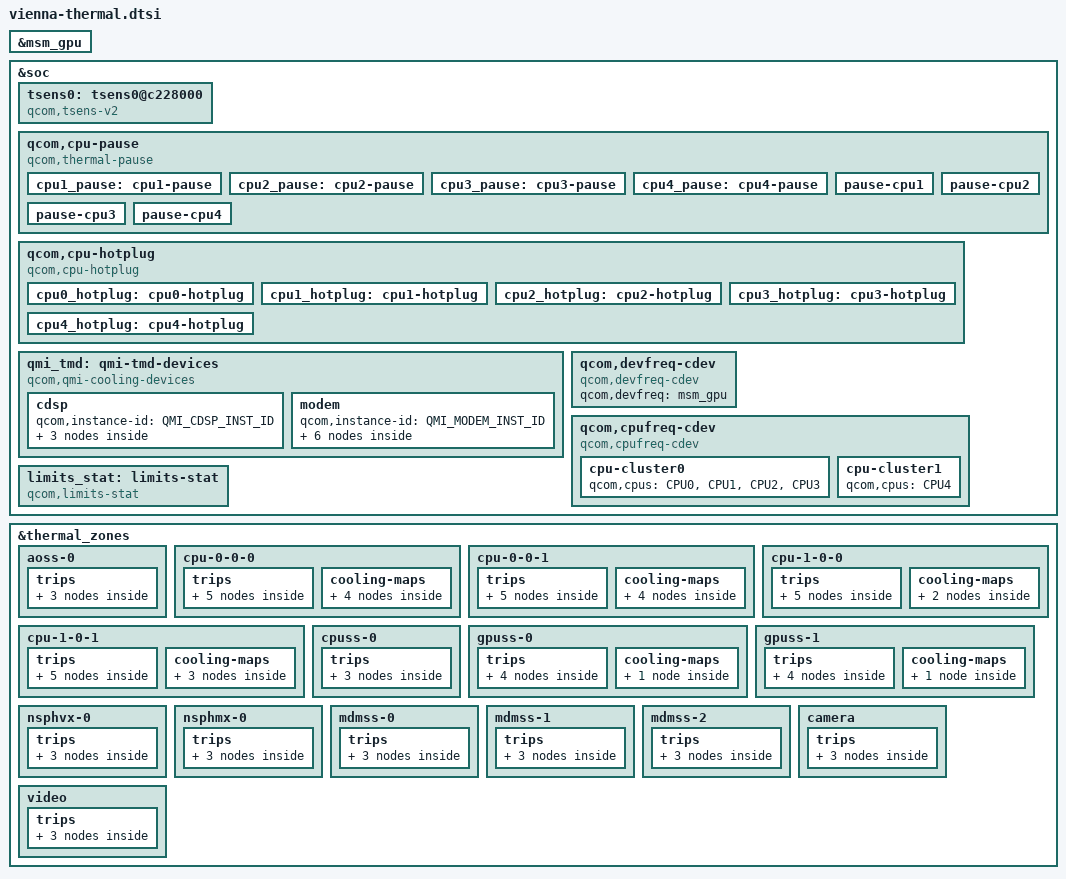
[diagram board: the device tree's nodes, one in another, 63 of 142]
// SPDX-License-Identifier: BSD-3-Clause
/*
 * Copyright (c) Qualcomm Technologies, Inc. and/or its subsidiaries.
 */

#include <dt-bindings/thermal/thermal_qti.h>

&msm_gpu {
	#cooling-cells = <2>;
};

&soc {
	tsens0: tsens0@c228000 {
		compatible = "qcom,tsens-v2";
		reg = <0xc228000 0x1ff>, /* TM */
				<0xc222000 0x1ff>; /* SROT */
		#qcom,sensors = <16>;
		interrupts = <GIC_SPI 482 IRQ_TYPE_LEVEL_HIGH>,
				<GIC_SPI 288 IRQ_TYPE_LEVEL_HIGH>;
		interrupt-names = "uplow","critical";
		#thermal-sensor-cells = <1>;
	};

	qcom,cpu-pause {
		compatible = "qcom,thermal-pause";

		cpu1_pause: cpu1-pause {
			qcom,cpus = <&CPU1>;
			qcom,cdev-alias = "thermal-pause-2";
			#cooling-cells = <2>;
		};

		cpu2_pause: cpu2-pause {
			qcom,cpus = <&CPU2>;
			qcom,cdev-alias = "thermal-pause-4";
			#cooling-cells = <2>;
		};

		cpu3_pause: cpu3-pause {
			qcom,cpus = <&CPU3>;
			qcom,cdev-alias = "thermal-pause-8";
			#cooling-cells = <2>;
		};

		cpu4_pause: cpu4-pause {
			qcom,cpus = <&CPU4>;
			qcom,cdev-alias = "thermal-pause-10";
			#cooling-cells = <2>;
		};


		/* Thermal-engine cooling devices */

		pause-cpu1 {
			qcom,cpus = <&CPU1>;
			qcom,cdev-alias = "pause-cpu1";
		};

		pause-cpu2 {
			qcom,cpus = <&CPU2>;
			qcom,cdev-alias = "pause-cpu2";
		};

		pause-cpu3 {
			qcom,cpus = <&CPU3>;
			qcom,cdev-alias = "pause-cpu3";
		};

		pause-cpu4 {
			qcom,cpus = <&CPU4>;
			qcom,cdev-alias = "pause-cpu4";
		};

	};

	qcom,cpu-hotplug {
		compatible = "qcom,cpu-hotplug";

		cpu0_hotplug: cpu0-hotplug {
			qcom,cpu = <&CPU0>;
			qcom,cdev-alias = "cpu-hotplug0";
			#cooling-cells = <2>;
		};

		cpu1_hotplug: cpu1-hotplug {
			qcom,cpu = <&CPU1>;
			qcom,cdev-alias = "cpu-hotplug1";
			#cooling-cells = <2>;
		};

		cpu2_hotplug: cpu2-hotplug {
			qcom,cpu = <&CPU2>;
			qcom,cdev-alias = "cpu-hotplug2";
			#cooling-cells = <2>;
		};

		cpu3_hotplug: cpu3-hotplug {
			qcom,cpu = <&CPU3>;
			qcom,cdev-alias = "cpu-hotplug3";
			#cooling-cells = <2>;
		};

		cpu4_hotplug: cpu4-hotplug {
			qcom,cpu = <&CPU4>;
			qcom,cdev-alias = "cpu-hotplug4";
			#cooling-cells = <2>;
		};
	};

	qmi_tmd: qmi-tmd-devices {
		compatible = "qcom,qmi-cooling-devices";
		cdsp {
			qcom,instance-id = <QMI_CDSP_INST_ID>;

			cdsp_sw: cdsp_sw {
				qcom,qmi-dev-name = "cdsp_sw";
				#cooling-cells = <2>;
			};

			cdsp_sw_hvx: cdsp_sw_hvx {
				qcom,qmi-dev-name = "cdsp_sw_hvx";
				#cooling-cells = <2>;
			};

			cdsp_hw: cdsp_hw {
				qcom,qmi-dev-name = "cdsp_hw";
				#cooling-cells = <2>;
			};
		};

		modem {
			qcom,instance-id = <QMI_MODEM_INST_ID>;

			pa_lte_sdr0_dsc: pa_lte_sdr0_dsc {
				qcom,qmi-dev-name = "pa_lte_sdr0_dsc";
				#cooling-cells = <2>;
			};

			pa_nr_sdr0_dsc: pa_nr_sdr0_dsc {
				qcom,qmi-dev-name = "pa_nr_sdr0_dsc";
				#cooling-cells = <2>;
			};

			modem_lte_dsc: modem_lte_dsc {
				qcom,qmi-dev-name = "modem_lte_dsc";
				#cooling-cells = <2>;
			};

			modem_nr_1rx_dsc: modem_nr_1rx_dsc {
				qcom,qmi-dev-name = "modem_nr_1rx_dsc";
				#cooling-cells = <2>;
			};

			modem_nr_2rx_dsc: modem_nr_2rx_dsc {
				qcom,qmi-dev-name = "modem_nr_2rx_dsc";
				#cooling-cells = <2>;
			};

			modem_wlan: modem_wlan {
				qcom,qmi-dev-name = "wlan";
				#cooling-cells = <2>;
			};
		};
	};

	qcom,devfreq-cdev {
		compatible = "qcom,devfreq-cdev";
		qcom,devfreq = <&msm_gpu>;
	};

	qcom,cpufreq-cdev {
		compatible = "qcom,cpufreq-cdev";
		cpu-cluster0 {
			qcom,cpus = <&CPU0 &CPU1 &CPU2 &CPU3>;
		};

		cpu-cluster1 {
			qcom,cpus = <&CPU4>;
		};
	};

	limits_stat: limits-stat {
		compatible = "qcom,limits-stat";
		qcom,limits-stat-sensor-names = "aoss-0", "cpu-0-0-0", "cpu-0-0-1",
						"cpu-1-0-0", "cpu-1-0-1", "cpu-0",
						"gpuss-0", "gpuss-1","nsphvx-0","nsphmx-0",
						"mdmss-0", "mdmss-1", "mdmss-2", "camera", "video";
	};
};

&thermal_zones {
	aoss-0 {
		polling-delay-passive = <0>;
		polling-delay = <0>;
		thermal-sensors = <&tsens0 0>;
		trips {
			thermal-engine-config {
				temperature = <125000>;
				hysteresis = <5000>;
				type = "passive";
			};

			thermal-hal-config {
				temperature = <95000>;
				hysteresis = <5000>;
				type = "passive";
			};

			reset-mon-cfg {
				temperature = <115000>;
				hysteresis = <5000>;
				type = "hot";
			};

		};
	};

	cpu-0-0-0 {
		polling-delay-passive = <0>;
		polling-delay = <0>;
		thermal-sensors = <&tsens0 1>;
		trips {
			thermal-engine-config {
				temperature = <125000>;
				hysteresis = <5000>;
				type = "passive";
			};

			thermal-hal-config {
				temperature = <95000>;
				hysteresis = <5000>;
				type = "passive";
			};

			reset-mon-cfg {
				temperature = <115000>;
				hysteresis = <5000>;
				type = "hot";
			};

			cpu00_config: cpu00-config {
				temperature = <110000>;
				hysteresis = <10000>;
				type = "passive";
			};

			cpu00_config_1: cpu00-config-1 {
				temperature = <112000>;
				hysteresis = <10000>;
				type = "passive";
			};

		};

		cooling-maps {
			cpu00_cdev0 {
				trip = <&cpu00_config>;
				cooling-device = <&cpu1_pause 0 1>;
			};

			cpu00_cdev1 {
				trip = <&cpu00_config>;
				cooling-device = <&cpu2_pause 0 1>;
			};

			cpu00_cdev2 {
				trip = <&cpu00_config>;
				cooling-device = <&cpu3_pause 0 1>;
			};

			cpu00_cdev3 {
				trip = <&cpu00_config_1>;
				cooling-device = <&cpu1_hotplug 0 1>;
			};
		};
	};

	cpu-0-0-1 {
		polling-delay-passive = <0>;
		polling-delay = <0>;
		thermal-sensors = <&tsens0 2>;
		trips {
			thermal-engine-config {
				temperature = <125000>;
				hysteresis = <5000>;
				type = "passive";
			};

			thermal-hal-config {
				temperature = <95000>;
				hysteresis = <5000>;
				type = "passive";
			};

			reset-mon-cfg {
				temperature = <115000>;
				hysteresis = <5000>;
				type = "hot";
			};

			cpu01_config: cpu01-config {
				temperature = <110000>;
				hysteresis = <10000>;
				type = "passive";
			};

			cpu01_config_1: cpu01-config-1 {
				temperature = <112000>;
				hysteresis = <10000>;
				type = "passive";
			};

		};

		cooling-maps {
			cpu01_cdev0 {
				trip = <&cpu01_config>;
				cooling-device = <&cpu1_pause 0 1>;
			};

			cpu01_cdev1 {
				trip = <&cpu01_config>;
				cooling-device = <&cpu2_pause 0 1>;
			};

			cpu01_cdev2 {
				trip = <&cpu01_config>;
				cooling-device = <&cpu3_pause 0 1>;
			};

			cpu01_cdev3 {
				trip = <&cpu01_config_1>;
				cooling-device = <&cpu1_hotplug 0 1>;
			};
		};
	};

	cpu-1-0-0 {
		polling-delay-passive = <0>;
		polling-delay = <0>;
		thermal-sensors = <&tsens0 3>;
		trips {
			thermal-engine-config {
				temperature = <125000>;
				hysteresis = <5000>;
				type = "passive";
			};

			thermal-hal-config {
				temperature = <95000>;
				hysteresis = <5000>;
				type = "passive";
			};

			reset-mon-cfg {
				temperature = <115000>;
				hysteresis = <5000>;
				type = "hot";
			};

			cpu10_config: cpu10-config {
				temperature = <110000>;
				hysteresis = <10000>;
				type = "passive";
			};

			cpu10_config_1: cpu10-config-1 {
				temperature = <112000>;
				hysteresis = <10000>;
				type = "passive";
			};

		};

		cooling-maps {
			cpu10_cdev0 {
				trip = <&cpu10_config>;
				cooling-device = <&cpu4_pause 0 1>;
			};

			cpu10_cdev1 {
				trip = <&cpu10_config_1>;
				cooling-device = <&cpu4_hotplug 0 1>;
			};
		};
	};

	cpu-1-0-1 {
		polling-delay-passive = <0>;
		polling-delay = <0>;
		thermal-sensors = <&tsens0 4>;
		trips {
			thermal-engine-config {
				temperature = <125000>;
				hysteresis = <5000>;
				type = "passive";
			};

			thermal-hal-config {
				temperature = <95000>;
				hysteresis = <5000>;
				type = "passive";
			};

			reset-mon-cfg {
				temperature = <115000>;
				hysteresis = <5000>;
				type = "hot";
			};

			cpu11_config: cpu11-config {
				temperature = <110000>;
				hysteresis = <10000>;
				type = "passive";
			};

			cpu11_config_1: cpu11-config-1 {
				temperature = <112000>;
				hysteresis = <10000>;
				type = "passive";
			};

		};

		cooling-maps {
			cpu11_cdev0 {
				trip = <&cpu11_config>;
				cooling-device = <&cpu4_pause 0 1>;
			};

			cpu11_cdev1 {
				trip = <&cpu11_config_1>;
				cooling-device = <&cpu1_hotplug 0 1>;
			};

			cpu11_cdev2 {
				trip = <&cpu11_config_1>;
				cooling-device = <&cpu4_hotplug 0 1>;
			};
		};
	};

	cpuss-0 {
		polling-delay-passive = <0>;
		polling-delay = <0>;
		thermal-sensors = <&tsens0 5>;
		trips {
			thermal-engine-config {
				temperature = <125000>;
				hysteresis = <5000>;
				type = "passive";
			};

			thermal-hal-config {
				temperature = <95000>;
				hysteresis = <5000>;
				type = "passive";
			};

			reset-mon-cfg {
				temperature = <115000>;
				hysteresis = <5000>;
				type = "hot";
			};

		};
	};

	gpuss-0 {
		polling-delay-passive = <0>;
		polling-delay = <0>;
		thermal-sensors = <&tsens0 6>;
		trips {
			thermal-engine-config {
				temperature = <125000>;
				hysteresis = <5000>;
				type = "passive";
			};

			thermal-hal-config {
				temperature = <95000>;
				hysteresis = <5000>;
				type = "passive";
			};

			reset-mon-cfg {
				temperature = <115000>;
				hysteresis = <5000>;
				type = "hot";
			};

			gpu0_tj_cfg: tj_cfg {
				temperature = <95000>;
				hysteresis = <5000>;
				type = "passive";
			};
		};

		cooling-maps {
			gpu0_cdev {
				trip = <&gpu0_tj_cfg>;
				cooling-device = <&msm_gpu 0 THERMAL_NO_LIMIT>;
			};
		};
	};

	gpuss-1 {
		polling-delay-passive = <0>;
		polling-delay = <0>;
		thermal-sensors = <&tsens0 7>;
		trips {
			thermal-engine-config {
				temperature = <125000>;
				hysteresis = <5000>;
				type = "passive";
			};

			thermal-hal-config {
				temperature = <95000>;
				hysteresis = <5000>;
				type = "passive";
			};

			reset-mon-cfg {
				temperature = <115000>;
				hysteresis = <5000>;
				type = "hot";
			};

			gpu1_tj_cfg: tj_cfg {
				temperature = <95000>;
				hysteresis = <5000>;
				type = "passive";
			};
		};

		cooling-maps {
			gpu1_cdev {
				trip = <&gpu1_tj_cfg>;
				cooling-device = <&msm_gpu 0 THERMAL_NO_LIMIT>;
			};
		};
	};

	nsphvx-0 {
		polling-delay-passive = <0>;
		polling-delay = <0>;
		thermal-sensors = <&tsens0 8>;
		trips {
			thermal-engine-config {
				temperature = <125000>;
				hysteresis = <5000>;
				type = "passive";
			};

			thermal-hal-config {
				temperature = <95000>;
				hysteresis = <5000>;
				type = "passive";
			};

			reset-mon-cfg {
				temperature = <115000>;
				hysteresis = <5000>;
				type = "hot";
			};

		};
	};

	nsphmx-0 {
		polling-delay-passive = <0>;
		polling-delay = <0>;
		thermal-sensors = <&tsens0 10>;
		trips {
			thermal-engine-config {
				temperature = <125000>;
				hysteresis = <5000>;
				type = "passive";
			};

			thermal-hal-config {
				temperature = <95000>;
				hysteresis = <5000>;
				type = "passive";
			};

			reset-mon-cfg {
				temperature = <115000>;
				hysteresis = <5000>;
				type = "hot";
			};

		};
	};

	mdmss-0 {
		polling-delay-passive = <0>;
		polling-delay = <0>;
		thermal-sensors = <&tsens0 11>;
		trips {
			thermal-engine-config {
				temperature = <125000>;
				hysteresis = <5000>;
				type = "passive";
			};

			thermal-hal-config {
				temperature = <95000>;
				hysteresis = <5000>;
				type = "passive";
			};

			reset-mon-cfg {
				temperature = <115000>;
				hysteresis = <5000>;
				type = "hot";
			};

		};
	};

	mdmss-1 {
		polling-delay-passive = <0>;
		polling-delay = <0>;
		thermal-sensors = <&tsens0 12>;
		trips {
			thermal-engine-config {
				temperature = <125000>;
				hysteresis = <5000>;
				type = "passive";
			};

			thermal-hal-config {
				temperature = <95000>;
				hysteresis = <5000>;
				type = "passive";
			};

			reset-mon-cfg {
				temperature = <115000>;
				hysteresis = <5000>;
				type = "hot";
			};

		};
	};

	mdmss-2 {
		polling-delay-passive = <0>;
		polling-delay = <0>;
		thermal-sensors = <&tsens0 13>;
		trips {
			thermal-engine-config {
				temperature = <125000>;
				hysteresis = <5000>;
				type = "passive";
			};

			thermal-hal-config {
				temperature = <95000>;
				hysteresis = <5000>;
				type = "passive";
			};

			reset-mon-cfg {
				temperature = <115000>;
				hysteresis = <5000>;
				type = "hot";
			};

		};
	};

	camera {
		polling-delay-passive = <0>;
		polling-delay = <0>;
		thermal-sensors = <&tsens0 14>;
		trips {
			thermal-engine-config {
				temperature = <125000>;
				hysteresis = <5000>;
				type = "passive";
			};

			thermal-hal-config {
				temperature = <95000>;
				hysteresis = <5000>;
				type = "passive";
			};

			reset-mon-cfg {
				temperature = <115000>;
				hysteresis = <5000>;
				type = "hot";
			};

		};
	};

	video {
		polling-delay-passive = <0>;
		polling-delay = <0>;
		thermal-sensors = <&tsens0 15>;
		trips {
			thermal-engine-config {
				temperature = <125000>;
				hysteresis = <5000>;
				type = "passive";
			};

			thermal-hal-config {
				temperature = <95000>;
				hysteresis = <5000>;
				type = "passive";
			};

			reset-mon-cfg {
				temperature = <115000>;
				hysteresis = <5000>;
				type = "hot";
			};

		};
	};
};
